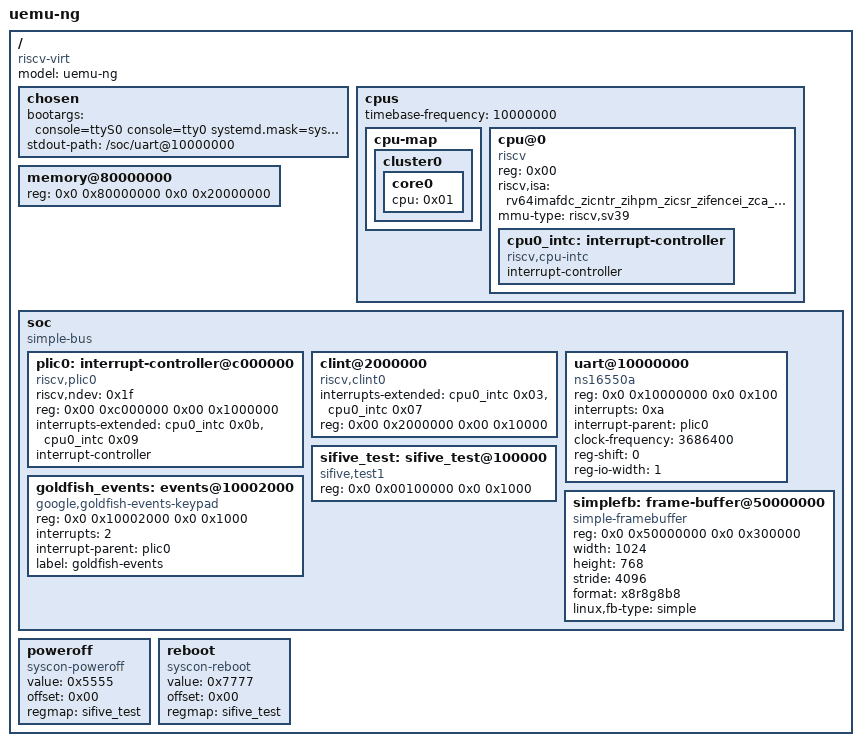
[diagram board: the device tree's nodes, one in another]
/dts-v1/;

/ {
    #address-cells = <0x02>;
    #size-cells = <0x02>;
    compatible = "riscv-virt";
    model = "uemu-ng";

    chosen {
        bootargs = "console=ttyS0 console=tty0 systemd.mask=systemd-resolved.service";
        stdout-path = "/soc/uart@10000000";
    };

    cpus {
        #address-cells = <0x01>;
        #size-cells = <0x00>;
        
        timebase-frequency = <10000000>;

        cpu-map {
            cluster0 {
                core0 {
                    cpu = <0x01>;
                };
            };
        };

        cpu@0 {
            phandle = <0x01>;
            device_type = "cpu";
            reg = <0x00>;
            status = "okay";
            compatible = "riscv";
            riscv,isa = "rv64imafdc_zicntr_zihpm_zicsr_zifencei_zca_zcd_sstc_svadu";
            mmu-type = "riscv,sv39";

            cpu0_intc: interrupt-controller {
                #interrupt-cells = <0x01>;
                interrupt-controller;
                compatible = "riscv,cpu-intc";
                phandle = <0x02>;
            };
        };
    };

    memory@80000000 {
        device_type = "memory";
        reg = <0x0 0x80000000 0x0 0x20000000>; 
    };

    soc {
        #address-cells = <0x02>;
        #size-cells = <0x02>;
        compatible = "simple-bus";
        ranges;

        plic0: interrupt-controller@c000000 {
            phandle = <0x03>;
            riscv,ndev = <0x1f>; 
            reg = <0x00 0xc000000 0x00 0x1000000>;
            interrupts-extended = <&cpu0_intc 0x0b &cpu0_intc 0x09>;
            interrupt-controller;
            compatible = "riscv,plic0";
            #interrupt-cells = <0x01>;
            #address-cells = <0x00>;
        };

        clint@2000000 {
            compatible = "riscv,clint0";
            interrupts-extended = <&cpu0_intc 0x03 &cpu0_intc 0x07>;
            reg = <0x00 0x2000000 0x00 0x10000>;
        };

        uart@10000000 {
            compatible = "ns16550a";
            reg = <0x0 0x10000000 0x0 0x100>;
            interrupts = <0xa>; 
            interrupt-parent = <&plic0>;
            clock-frequency = <3686400>; 
            reg-shift = <0>;
            reg-io-width = <1>;
        };

        sifive_test: sifive_test@100000 {
            phandle = <0x04>;
            reg = <0x0 0x00100000 0x0 0x1000>;
            compatible = "sifive,test1", "sifive,test0", "syscon";
        };

        goldfish_events: events@10002000 {
            compatible = "google,goldfish-events-keypad";
            reg = <0x0 0x10002000 0x0 0x1000>;
            interrupts = <2>;
            interrupt-parent = <&plic0>;
            label = "goldfish-events";
            status = "okay";
        };

        simplefb: frame-buffer@50000000 {
            compatible = "simple-framebuffer";
            reg = <0x0 0x50000000 0x0 0x300000>;
            width = <1024>;
            height = <768>;
            stride = <4096>;
            format = "x8r8g8b8";
            status = "okay";
            linux,fb-type = "simple";
        };
    };

    poweroff {
        value = <0x5555>;
        offset = <0x00>;
        regmap = <&sifive_test>;
        compatible = "syscon-poweroff";
    };

    reboot {
        value = <0x7777>;
        offset = <0x00>;
        regmap = <&sifive_test>;
        compatible = "syscon-reboot";
    };
};
